# DSS0_COMMON register map
Vendor: Texas Instruments
Peripheral module from a debugger description file (folder am65x).
Registers are 32-bit, access per field, reset 0x0 unless marked. A register's access mark holds for its fields unless they carry their own. Offsets are as the file gives them; lines under a group give offsets from that group; [hi:lo] are bit positions; {n}, {i} and the like mark numbered series; 'fields as' and 'values as' point back to an identical list; <NAME> marks a mode.

## DSS0_COMMON
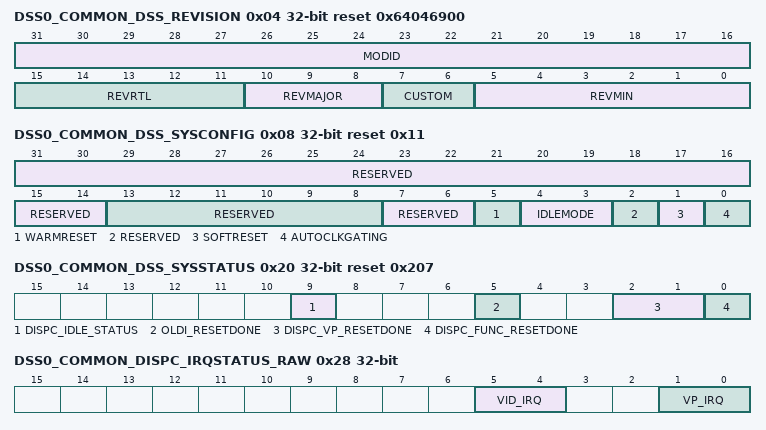
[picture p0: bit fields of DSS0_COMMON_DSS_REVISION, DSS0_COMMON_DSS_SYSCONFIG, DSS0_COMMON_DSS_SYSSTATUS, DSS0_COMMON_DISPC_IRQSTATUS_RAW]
0x04 DSS0_COMMON_DSS_REVISION ro reset 0x64046900 — This register contains the K3_DSS revision number
  [31:16] MODID — Module ID Field
  [15:11] REVRTL — RTL Revision
  [10:8] REVMAJOR — Major Revision
  [7:6] CUSTOM
  [5:0] REVMIN — Minor Revision
0x08 DSS0_COMMON_DSS_SYSCONFIG reset 0x11 — This register controls various parameters related to software reset and IP idle
  [31:14] RESERVED ro — Write 0's for future compatibility. Read returns 0
  [13:8] RESERVED ro — Write 0's for future compatibility. Read returns 0
  [7:6] RESERVED ro — Write 0's for future compatibility. Read returns 0
  [5] WARMRESET rw — Warm reset. Setting this bit to 1 triggers a module warm reset. The bit is automatically reset by the hardware. During read, it always returns 0. The warm reset keeps the configuration registers unchanged
  [4:3] IDLEMODE rw — Deprecated
  [2] RESERVED ro — Write 0's for future compatibility. Read returns 0
  [1] SOFTRESET rw — Software reset. Setting this bit to 1 triggers a module reset. The bit is automatically reset by the hardware. During read, it always returns 0
  [0] AUTOCLKGATING rw — Internal clock gating strategy 0h = Clocks are free-running 1h = Automatic clock gating strategy is applied, clocks are gated based on module activity
0x20 DSS0_COMMON_DSS_SYSSTATUS ro reset 0x207 — This register provides status information about the module, excluding the interrupt status information
  [9] DISPC_IDLE_STATUS — Idle status of DISPC 0h = DISPC is not in Idle 1h = DISPC is in Idle
  [5] OLDI_RESETDONE — Reset status of OLDI 0h = Internal module reset is on-going 1h = Reset completed
  [2:1] DISPC_VP_RESETDONE — Reset status of VP pixel clock domain But [2] is for VP2. Bit [1] is for VP1 0h = Internal module reset is on-going 1h = Reset completed
  [0] DISPC_FUNC_RESETDONE — Reset status of DISPC Functional clock domain 0h = Internal module reset is on-going 1h = Reset completed
0x24 DSS0_COMMON_DISPC_IRQ_EOI — End-Of-Interrupt register, to be used if pulse interrupts are used The EOI register is used to re-trigger the pulse interrupt signal to ensure that any nested interrupt events are serviced. The software interrupt handler must write to the EOI register at the end of the current interrupt processing routine, so that new events can re-trigger the pulse interrupt signal again. For level interrupt signals the EOI register is not functional and must not be used.
  [0] EOI wo — Write 1 to acknowledge a pulse IRQ 0h = Write-0 : No action 1h = Write-1 : End-of-Interrupt
0x28 DSS0_COMMON_DISPC_IRQSTATUS_RAW access not given — RAW Interrupt status. Raw status is set even if interrupt is not enabled. Write 1 to set the RAW status
  [5:4] VID_IRQ — VID IRQ STATUS. Register indicates the VIDEO pipeline[s] interrupt events. Bit [5] is for VIDL1 pipeline. Bit [4] is for VID pipeline. 0h = Write-0 : No action, Read-0 : No event pending 1h = Write-1 : Set event, Read-1 : IRQ event pending (access RW1S)
  [1:0] VP_IRQ — VP IRQ STATUS. Register indicates the Video Port[s] interrupt events. Bit [1] is for VP2. Bit [0] is for VP1. 0h = Write-0 : No action, Read-0 : No event pending 1h = Write-1 : Set event, Read-1 : IRQ event pending (access RW1S)
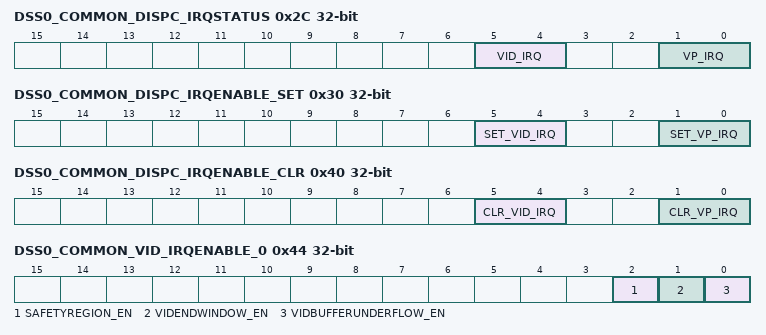
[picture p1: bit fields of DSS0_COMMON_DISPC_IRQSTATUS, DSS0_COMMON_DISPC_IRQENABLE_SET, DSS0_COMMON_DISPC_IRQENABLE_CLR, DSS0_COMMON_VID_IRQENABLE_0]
0x2C DSS0_COMMON_DISPC_IRQSTATUS access not given — Interrupt status. Enabled status, isn't set unless event is enabled. Write 1 to clear the status after interrupt has been serviced. RAW status also gets cleared, i.e. even if not enabled
  [5:4] VID_IRQ — VID IRQ STATUS. Register indicates the VIDEO pipeline[s] interrupt events. Bit [5] is for VIDL1 pipeline. Bit [4] is for VID pipeline. 0h = Write-0 : No action, Read-0 : No event pending 1h = Write-1 : Clear pending event, if any, Read-1 : IRQ event pending (access RW1C)
  [1:0] VP_IRQ — VP IRQ STATUS. Register indicates the Video Port[s] interrupt events. Bit [1] is for VP2. Bit [0] is for VP1. 0h = Write-0 : No action, Read-0 : No event pending 1h = Write-1 : Clear pending event, if any, Read-1 : IRQ event pending (access RW1C)
0x30 DSS0_COMMON_DISPC_IRQENABLE_SET access not given — SET Interrupt enable. Write 1 to set interrupt enable. Readout equal to corresponding _CLR register
  [5:4] SET_VID_IRQ — VID IRQ Bit [5] is for VIDL1 pipeline. Bit [4] is for VID pipeline. 0h = Write-0 : No action, Read-0 : Interrupt Disabled 1h = Write-1 : Enable interrupt, Read-1 : Interrupt Enabled (access RW1S)
  [1:0] SET_VP_IRQ — VP IRQ Bit [1] is for VP2. Bit [0] is for VP1. 0h = Write-0 : No action, Read-0 : Interrupt Disabled 1h = Write-1 : Enable interrupt, Read-1 : Interrupt Enabled (access RW1S)
0x40 DSS0_COMMON_DISPC_IRQENABLE_CLR access not given — CLR Interrupt enable. Write 1 to clear interrupt enable
  [5:4] CLR_VID_IRQ — VID IRQ Bit [5] is for VIDL1 pipeline. Bit [4] is for VID pipeline. 0h = Write-0 : No action, Read-0 : Interrupt Disabled 1h = Write-1 : Clear interrupt, Read-1 : Interrupt Enabled (access RW1C)
  [1:0] CLR_VP_IRQ — VP IRQ Bit [1] is for VP2. Bit [0] is for VP1. 0h = Write-0 : No action, Read-0 : Interrupt Disabled 1h = Write-1 : Clear interrupt, Read-1 : Interrupt Enabled (access RW1C)
0x44 DSS0_COMMON_VID_IRQENABLE_0 — This register allows to mask/unmask the VID_0 internal sources of interrupt, on an event-by-event basis
  [2] SAFETYREGION_EN rw — Safety Feature IRQ. This is raised when FrameFreeze is detected or data mismatch occurs within the safety region 0h = Event is masked 1h = Event generates an interrupt when it occurs
  [1] VIDENDWINDOW_EN rw — Video End Window. This is raised by the DMA engine when the full video data has been sent to the pipeline 0h = Event is masked 1h = Event generates an interrupt when it occurs
  [0] VIDBUFFERUNDERFLOW_EN rw — Video DMA Buffer Underflow. This is raised when the DMA buffer does not have the data requested by the Video pipeline 0h = Event is masked 1h = Event generates an interrupt when it occurs
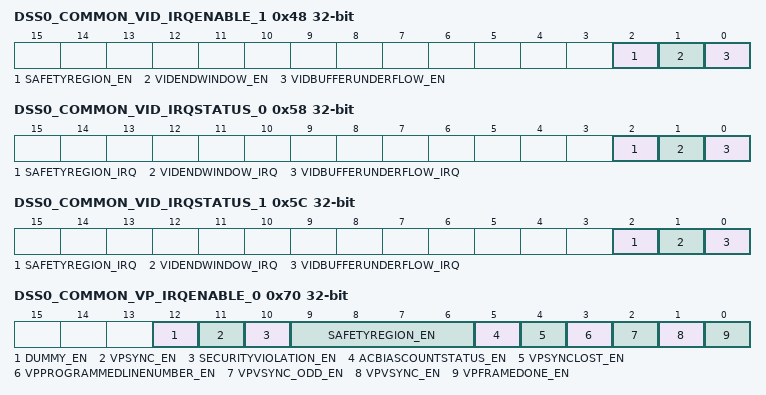
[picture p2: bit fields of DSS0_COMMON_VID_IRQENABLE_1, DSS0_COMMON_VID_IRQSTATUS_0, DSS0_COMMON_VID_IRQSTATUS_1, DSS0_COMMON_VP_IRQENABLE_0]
0x48 DSS0_COMMON_VID_IRQENABLE_1 — This register allows to mask/unmask the VIDL_0 internal sources of interrupt, on an event-by-event basis
  fields as DSS0_COMMON_VID_IRQENABLE_0
0x58 DSS0_COMMON_VID_IRQSTATUS_0 access not given — This register groups all the status of the VID_0 internal events that generate an interrupt. Write 1 to a clear a bit field
  [2] SAFETYREGION_IRQ — Safety Feature IRQ. This is raised when FrameFreeze is detected or data mismatch occurs within the safety region 0h = Write: Status is unchanged, Read: Event is not pending 1h = Write: Status is reset, Read: Event is Pending (access RW1C)
  [1] VIDENDWINDOW_IRQ — Video End Window. This is raised by the DMA engine when the full video data has been sent to the pipeline 0h = Write: Status is unchanged, Read: Event is not pending 1h = Write: Status is reset, Read: Event is Pending (access RW1C)
  [0] VIDBUFFERUNDERFLOW_IRQ — Video DMA Buffer Underflow. This is raised when the DMA buffer does not have the data requested by the Video pipeline 0h = Write: Status is unchanged, Read: Event is not pending 1h = Write: Status is reset, Read: Event is Pending (access RW1C)
0x5C DSS0_COMMON_VID_IRQSTATUS_1 access not given — This register groups all the status of the VIDL_0 internal events that generate an interrupt. Write 1 to a clear a bit field
  fields as DSS0_COMMON_VID_IRQSTATUS_0
0x70 DSS0_COMMON_VP_IRQENABLE_0 — This register allows to mask/unmask the VP_0 internal sources of interrupt, on an event-by-event basis
  [12] DUMMY_EN rw — Dummy IRQ for future use 0h = Event is masked 1h = Event generates an interrupt when it occurs
  [11] VPSYNC_EN rw — Go bit clear event 0h = Event is masked 1h = Event generates an interrupt when it occurs
  [10] SECURITYVIOLATION_EN rw — Security Violation interrupt for OVR/VP. Non-secure OVR/VP connected to secure VID 0h = Event is masked 1h = Event generates an interrupt when it occurs
  [9:6] SAFETYREGION_EN rw — Safety Feature IRQ. This is raised when FrameFreeze is detected or data mismatch occurs within the safety region. Bit [9] is for safety region 3. Bit [8] is for safety region 2. Bit [7] is for safety region 1. Bit [6] is for safety region 0. 0h = Event is masked 1h = Event generates an interrupt when it occurs
  [5] ACBIASCOUNTSTATUS_EN rw — AC BIAS transition counter has decremented to zero 0h = Event is masked 1h = Event generates an interrupt when it occurs
  [4] VPSYNCLOST_EN rw — Synchronization Lost for Video Port 0h = Event is masked 1h = Event generates an interrupt when it occurs
  [3] VPPROGRAMMEDLINENUMBER_EN rw — Programmed Line Number. It indicates that the scan of the display has reached the programmed user line number 0h = Event is masked 1h = Event generates an interrupt when it occurs
  [2] VPVSYNC_ODD_EN rw — VSYNC for odd field from interlace mode only 0h = Event is masked 1h = Event generates an interrupt when it occurs
  [1] VPVSYNC_EN rw — Vertical Synchronization for VP 0h = Event is masked 1h = Event generates an interrupt when it occurs
  [0] VPFRAMEDONE_EN rw — Frame Done for Video Port. VP output has been disabled by user. All the data have been sent 0h = Event is masked 1h = Event generates an interrupt when it occurs
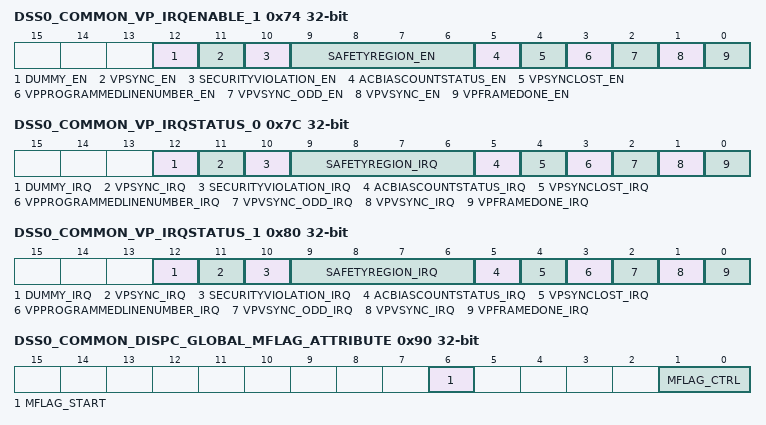
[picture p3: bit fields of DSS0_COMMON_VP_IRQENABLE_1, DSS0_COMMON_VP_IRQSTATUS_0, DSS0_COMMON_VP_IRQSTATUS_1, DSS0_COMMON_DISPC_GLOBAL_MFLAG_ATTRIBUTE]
0x74 DSS0_COMMON_VP_IRQENABLE_1 — This register allows to mask/unmask the VP_1 internal sources of interrupt, on an event-by-event basis
  fields as DSS0_COMMON_VP_IRQENABLE_0
0x7C DSS0_COMMON_VP_IRQSTATUS_0 access not given — This register groups all the status of the VP_0 internal events that generate an interrupt. Write 1 to a given bit resets this bit
  [12] DUMMY_IRQ — Dummy IRQ for future use 0h = Write: Status is unchanged, Read: Event is not pending 1h = Write: Status is reset, Read: Event is Pending (access RW1C)
  [11] VPSYNC_IRQ — Go bit clear event 0h = Write: Status is unchanged, Read: Event is not pending 1h = Write: Status is reset, Read: Event is Pending (access RW1C)
  [10] SECURITYVIOLATION_IRQ — Security Violation IRQ. Non-secure OVR/VP connected to secure VID 0h = Write: Status is unchanged, Read: Event is not pending 1h = Write: Status is reset, Read: Event is Pending (access RW1C)
  [9:6] SAFETYREGION_IRQ — Safety Feature IRQ. This is raised when FrameFreeze is detected or data mismatch occurs within the safety region. Bit [9] is for safety region 3. Bit [8] is for safety region 2. Bit [7] is for safety region 1. Bit [6] is for safety region 0. 0h = Write: Status is unchanged, Read: Event is not pending 1h = Write: Status is reset, Read: Event is Pending (access RW1C)
  [5] ACBIASCOUNTSTATUS_IRQ — AC BIAS transition counter has decremented to zero 0h = Write: Status is unchanged, Read: Event is not pending 1h = Write: Status is reset, Read: Event is Pending (access RW1C)
  [4] VPSYNCLOST_IRQ — Synchronization Lost on VP output. The required data are not output at the correct time due to too short blanking periods or stall of at least one pipelines associated with VP output 0h = Write: Status is unchanged, Read: Event is not pending 1h = Write: Status is reset, Read: Event is Pending (access RW1C)
  [3] VPPROGRAMMEDLINENUMBER_IRQ — Programmed Line Number. It indicates that the scan of the display has reached the programmed user line number 0h = Write: Status is unchanged, Read: Event is not pending 1h = Write: Status is reset, Read: Event is Pending (access RW1C)
  [2] VPVSYNC_ODD_IRQ — VSYNC for odd field. For interlace mode only 0h = Write: Status is unchanged, Read: Event is not pending 1h = Write: Status is reset, Read: Event is Pending (access RW1C)
  [1] VPVSYNC_IRQ — Vertical Synchronization for VP output. It is used as VSYNC_EVEN in case of interlace mode 0h = Write: Status is unchanged, Read: Event is not pending 1h = Write: Status is reset, Read: Event is Pending (access RW1C)
  [0] VPFRAMEDONE_IRQ — Frame Done for VP. VP output has been disabled by user All the data have been sent 0h = Write: Status is unchanged, Read: Event is not pending 1h = Write: Status is reset, Read: Event is Pending (access RW1C)
0x80 DSS0_COMMON_VP_IRQSTATUS_1 access not given — This register groups all the status of the VP_1 internal events that generate an interrupt. Write 1 to a given bit resets this bit
  fields as DSS0_COMMON_VP_IRQSTATUS_0
0x90 DSS0_COMMON_DISPC_GLOBAL_MFLAG_ATTRIBUTE — MFLAG control register
  [6] MFLAG_START rw — MFLAG_START for DMA master port 0h = When the DMA buffer is empty at the beginning of the frame, the MFLAG of each pipe is kept at 0 until PRELOAD is reached, then based on MFLAG_CTRL, MFLAG is generated and internal logic is arbitrating between pipeline requests 1h = Even at the beginning of the frame when the DMA buffer is empty, MFLAG_CTRL is used to determine how MFLAG dedicated to each pipe signal shall be driven
  [1:0] MFLAG_CTRL rw — MFLAG_CTRL for DMA master port 0h = MFLAG mechanism is disabled: MFLAG out band signal is set to 0 1h = MFLAG mechanism is enabled: MFLAG out band signal is always set to 1 2h = MFLAG mechanism is enabled and MFLAG out band signal is dynamically set to 0 or 1 depending on the MFLAG rules
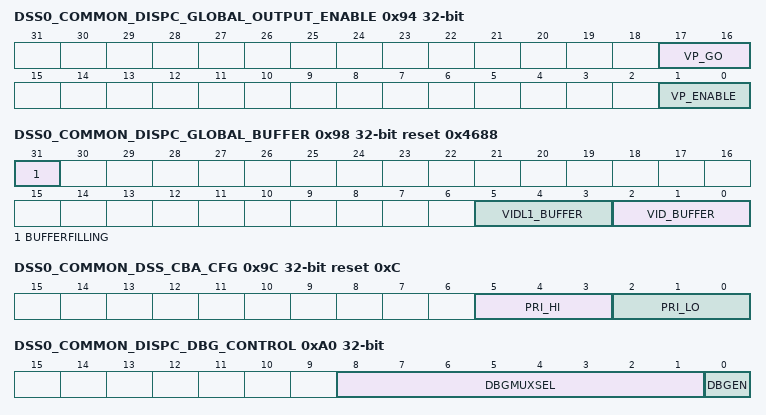
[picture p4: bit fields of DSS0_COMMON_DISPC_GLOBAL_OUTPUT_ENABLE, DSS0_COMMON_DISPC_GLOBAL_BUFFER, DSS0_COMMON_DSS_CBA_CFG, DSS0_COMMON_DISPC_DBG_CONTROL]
0x94 DSS0_COMMON_DISPC_GLOBAL_OUTPUT_ENABLE — DISPC global output enable register. The ENABLE or GO bit for a particular output port is set when either the corresponding bit in this register is set or the corresponding bit within the sub-module is set. This register allows enabling multiple outputs synchronously [simultaneously], which is not possible if the ENABLE/GO bits are present only within the sub-module
  [17:16] VP_GO rw — Global GO Command for the VP output(s). It is used to synchronize the pipelines associated with the VP output. wr: immediate Bit [17] is for VP2. Bit [16] is for VP1. 0h = The hardware has finished updating the internal shadow registers of the pipeline(s) connected to the VP output using the user values. The hardware resets the bit when the update is completed 1h = The user has finished to program the shadow registers of the pipeline(s) associated with the VP output and the hardware can update the internal registers at the VFP start period
  [1:0] VP_ENABLE rw — Global VP Enable. Bit [1] is for VP2. Bit [0] is for VP1. 0h = VP port is disabled 1h = VP port is enabled
0x98 DSS0_COMMON_DISPC_GLOBAL_BUFFER reset 0x4688 — The register configures the DMA buffers allocations to the pipelines for DMA
  [31] BUFFERFILLING rw — Controls if the DMA buffers are re-filled only when the LOW threshold is reached or if all DMA buffers are re-filled when at least one of them reaches the LOW threshold. 0h = Each DMA buffer is re-filled when it reaches LOW threshold. 1h = All DMA buffers are re-filled up to high threshold when at least one of them reaches the LOW threshold. Only active DMA buffers shall be considered and when reaching the end of the frame the DMA buffer goes to empty condition so no need to fill it again.
  [5:3] VIDL1_BUFFER rw — VIDL1 DMA buffer allocation to one of the pipelines. 0h = DMA buffer allocated to the VID pipeline. 1h = DMA buffer allocated to the VIDL1 pipeline.
  [2:0] VID_BUFFER rw — VID DMA buffer allocation to one of the pipelines 0h = DMA buffer allocated to the VID pipeline. 1h = DMA buffer allocated to the VIDL1 pipeline.
0x9C DSS0_COMMON_DSS_CBA_CFG reset 0xC — This register contains CBA specific config bits in DSS
  [5:3] PRI_HI rw — The value sent out on the PRI_HI bus from DSS to CBA Indicates the priority level for high-priority [MFLAG] transactions. Value of 0x0 indicates highest priority Value of 0x7 indicates lowest priority
  [2:0] PRI_LO rw — The value sent out on the PRI_LO bus from DSS to CBA Indicates the priority level for normal [non-MFLAG] transactions. Value of 0x0 indicates highest priority Value of 0x7 indicates lowest priority
0xA0 DSS0_COMMON_DISPC_DBG_CONTROL — DISPC debug status control register
  [8:1] DBGMUXSEL rw — Mux select for the debug status 00h = 8 values to select any 4bytes, order from LSB 4bytes to MSB 4bytes, at a time from the 32byte VID debug bus 08h = 8 values to select any 4bytes, order from LSB 4bytes to MSB 4bytes, at a time from the 32byte VIDL1 debug bus 11h = Select OVR1 debug bus, 4bytes 12h = Select OVR2 debug bus, 4bytes 13h = Select VP1 debug bus, 8bytes 15h = Select VP2 debug bus, 8bytes 17h = Select MISC debug bus, 4bytes
  [0] DBGEN rw — Enable debug ports 0h = Disable 1h = Enable
0xA4 DSS0_COMMON_DISPC_DBG_STATUS ro — DISPC debug status register
  [31:0] DBGOUT — Debug status
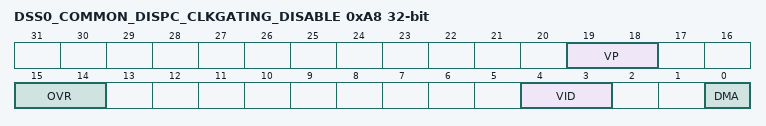
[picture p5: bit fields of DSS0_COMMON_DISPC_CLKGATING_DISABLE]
0xA8 DSS0_COMMON_DISPC_CLKGATING_DISABLE — Register to control clock gating at DISPC sub-module level
  [19:18] VP rw — Clock gating control for VP. Bit [19] is for VP2. Bit [18] is for VP1. 0h = Clock-Gating is enabled 1h = Clock-gating is disabled. Clocks are free running
  [15:14] OVR rw — Clock gating control for OVR. Bit [15] is for OVR2. Bit [14] is for OVR1. 0h = Clock-Gating is enabled 1h = Clock-gating is disabled. Clocks are free running
  [4:3] VID rw — Clock gating control for VID. Bit [4] is for VIDL1. Bit [3] is for VID. 0h = Clock-Gating is enabled 1h = Clock-gating is disabled. Clocks are free running
  [0] DMA rw — Clock gating control for DMA. 0h = Clock-Gating is enabled 1h = Clock-gating is disabled. Clocks are free running
0xAC DSS0_COMMON_DISPC_SECURE_DISABLE — Disable security settings throughout DSS IP. COMMON_1.DISPC_SECURE bits are honoured only if COMMON. =0
  [0] SECURE_DISABLE rw — Secure disable bit 0h = Secure bits, in COMMON1_DISPC_SECURE register, are active. 1h = Secure bits, in COMMON1_DISPC_SECURE register, are not active and IP will behave as non-secure.
